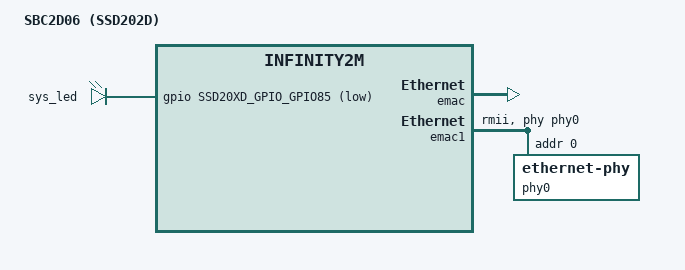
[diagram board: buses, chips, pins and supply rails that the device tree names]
// SPDX-License-Identifier: GPL-2.0-or-later
/*
 * Copyright (c) 2021 thingy.jp.
 * Author: Daniel Palmer <daniel@thingy.jp>
 */

/dts-v1/;
#include "mstar-infinity2m-ssd202d-som2d01.dts"

/ {
	model = "SBC2D06 (SSD202D)";
	compatible = "ido,sbc2d06", "mstar,infinity2m";

	leds {
		compatible = "gpio-leds";
		sys_led {
			gpios = <&gpio SSD20XD_GPIO_GPIO85 GPIO_ACTIVE_LOW>;
			linux,default-trigger = "activity";
		};
	};
};

&emac {
	pinctrl-names = "default";
	pinctrl-0 = <&emac_mode1_pins>, <&pm_led_mode1_pins>;
	status = "okay";
};

&emac1 {
	status = "okay";
	phy-mode = "rmii";
	phy-handle = <&phy0>;

	#address-cells = <1>;
	#size-cells = <0>;
	phy0: ethernet-phy@0 {
		reg = <0x0>;
		phy-mode = "rmii";
	};
};
